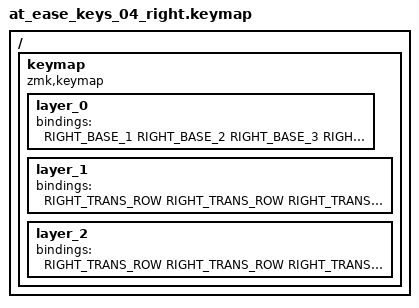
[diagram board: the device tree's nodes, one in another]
#include <behaviors.dtsi>
#include <dt-bindings/zmk/keys.h>

#define BASE 0
#define NUM  1
#define NAV  2

#define RIGHT_BASE_1  &kp Y, &kp U, &kp I, &kp O, &kp P, &kp MINUS, &kp AT
#define RIGHT_BASE_2  &kp H, &kp J, &kp K, &kp L, &kp SEMI, &kp COLON, &kp RBRC
#define RIGHT_BASE_3  &kp N, &kp M, &kp COMMA, &kp DOT, &kp FSLH, &kp KANA, &kp RSHFT
#define RIGHT_BASE_4  &kp RALT, &kp LEFT, &kp DOWN, &kp UP, &kp RIGHT, &none, &none

#define RIGHT_TRANS_ROW &trans, &trans, &trans, &trans, &trans, &trans, &trans

/ {
    keymap {
        compatible = "zmk,keymap";
        layer_0 { bindings = <RIGHT_BASE_1 RIGHT_BASE_2 RIGHT_BASE_3 RIGHT_BASE_4>; };
        layer_1 { bindings = <RIGHT_TRANS_ROW RIGHT_TRANS_ROW RIGHT_TRANS_ROW RIGHT_TRANS_ROW>; };
        layer_2 { bindings = <RIGHT_TRANS_ROW RIGHT_TRANS_ROW RIGHT_TRANS_ROW RIGHT_TRANS_ROW>; };
    };
};
